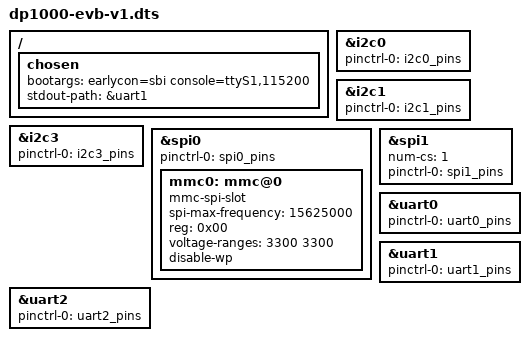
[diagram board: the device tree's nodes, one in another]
// SPDX-License-Identifier: GPL-2.0
/*
 * Copyright(C) 2025 UltraRISC Technology (Shanghai) Co., Ltd.
 */

#include "dp1000-evb-pinctrl.dtsi"
#include <dt-bindings/iio/temperature/thermocouple.h>

/ {
	chosen {
		bootargs = "earlycon=sbi console=ttyS1,115200";
		stdout-path = &uart1;
	};
};

&i2c0 {
	pinctrl-names = "default";
	pinctrl-0 = <&i2c0_pins>;
};

&i2c1 {
	pinctrl-names = "default";
	pinctrl-0 = <&i2c1_pins>;
};

&i2c3 {
	pinctrl-names = "default";
	pinctrl-0 = <&i2c3_pins>;
};

&spi0 {
	pinctrl-names = "default";
	pinctrl-0 = <&spi0_pins>;

	mmc0: mmc@0 {
		compatible = "mmc-spi-slot";
		spi-max-frequency = <15625000>;
		reg = <0x00>;
		voltage-ranges = <3300 3300>;
		disable-wp;
	};
};

&spi1 {
	num-cs = <1>;

	pinctrl-names = "default";
	pinctrl-0 = <&spi1_pins>;
};

&uart0 {
	pinctrl-names = "default";
	pinctrl-0 = <&uart0_pins>;
};

&uart1 {
	pinctrl-names = "default";
	pinctrl-0 = <&uart1_pins>;
};

&uart2 {
	pinctrl-names = "default";
	pinctrl-0 = <&uart2_pins>;
};
